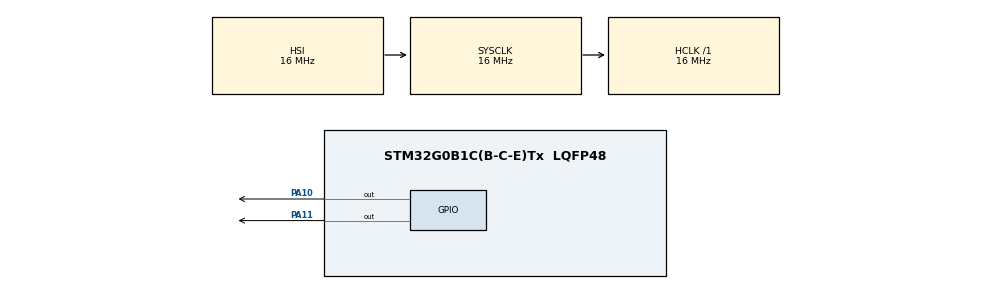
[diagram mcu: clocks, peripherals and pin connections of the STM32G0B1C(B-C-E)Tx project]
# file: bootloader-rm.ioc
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Mcu.Family=STM32G0
Mcu.Name=STM32G0B1C(B-C-E)Tx
Mcu.Package=LQFP48
PA10.Signal=GPIO_Output
PA11\ [PA9].Signal=GPIO_Output
PA2.Signal=USART2_TX
PA3.Signal=USART2_RX
ProjectManager.HeapSize=0x200
ProjectManager.StackSize=0x400
ProjectManager.TargetToolchain=STM32CubeIDE
RCC.AHBFreq_Value=16000000
RCC.CortexFreq_Value=16000000
RCC.EXTERNAL_CLOCK_VALUE=48000
RCC.HCLKFreq_Value=16000000
RCC.HSE_VALUE=8000000
RCC.HSI48_VALUE=48000000
RCC.HSI_VALUE=16000000
RCC.LSE_VALUE=32768
RCC.SYSCLKFreq_VALUE=16000000
RCC.USBFreq_Value=48000000
RCC.VCOOutputFreq_Value=128000000
VP_SYS_VS_DBSignals.Mode=DisableDeadBatterySignals
board=custom

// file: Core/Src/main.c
/* USER CODE BEGIN Header */
/**
  ******************************************************************************
  * @file           : main.c
  * @brief          : Main program body
  ******************************************************************************
  * @attention
  *
  * Copyright (c) 2024 STMicroelectronics.
  * All rights reserved.
  *
  * This software is licensed under terms that can be found in the LICENSE file
  * in the root directory of this software component.
  * If no LICENSE file comes with this software, it is provided AS-IS.
  *
  ******************************************************************************
  */
/* USER CODE END Header */
#include "main.h"

/* USER CODE BEGIN Includes */
#include "bootloader.h"
/* USER CODE END Includes */

void SystemClock_Config(void);
static void MX_GPIO_Init(void);

int main(void)
{

  /* MCU Configuration--------------------------------------------------------*/

  /* Reset of all peripherals, Initializes the Flash interface and the Systick. */
  HAL_Init();

  /* Configure the system clock */
  SystemClock_Config();

  /* Initialize all configured peripherals */
  MX_GPIO_Init();
  /* USER CODE BEGIN 2 */

  // Make sure that the boot0 pin will work
  if ( (FLASH->OPTR & FLASH_OPTR_nBOOT_SEL) != 0 ){
	  int a = 5;
//	  while(HAL_FLASH_Unlock() != HAL_OK);
//	  while(HAL_FLASH_OB_Unlock() != HAL_OK);
//
//	  /* Enable legacy mode (BOOT0 bit defined by BOOT0 pin) */
//	  /* by clearing the nBOOT_SELection bit */
//	  FLASH->OPTR &= ~FLASH_OPTR_nBOOT_SEL;
//
//	  /* check if there is any flash operation */
//	  while( (FLASH->SR & FLASH_SR_BSY1) != 0 )
//	    ;
//
//	  /* start the option byte flash */
//	  FLASH->CR |= FLASH_CR_OPTSTRT;
//	  /* wait until flashing is done */
//	  while( (FLASH->SR & FLASH_SR_BSY1) != 0 )
//	    ;
//
//	  while(HAL_FLASH_OB_Lock() != HAL_OK);
//	  while(HAL_FLASH_Lock() != HAL_OK);
  }

  /* USER CODE END 2 */

  /* Infinite loop */
  while (1)
  {

    /* USER CODE BEGIN 3 */
	  bootloader_run();
  }
  /* USER CODE END 3 */
}

void SystemClock_Config(void)
{
  RCC_OscInitTypeDef RCC_OscInitStruct = {0};
  RCC_ClkInitTypeDef RCC_ClkInitStruct = {0};

  /** Configure the main internal regulator output voltage
  */
  HAL_PWREx_ControlVoltageScaling(PWR_REGULATOR_VOLTAGE_SCALE1);

  /** Initializes the RCC Oscillators according to the specified parameters
  * in the RCC_OscInitTypeDef structure.
  */
  RCC_OscInitStruct.OscillatorType = RCC_OSCILLATORTYPE_HSI;
  RCC_OscInitStruct.HSIState = RCC_HSI_ON;
  RCC_OscInitStruct.HSIDiv = RCC_HSI_DIV1;
  RCC_OscInitStruct.HSICalibrationValue = RCC_HSICALIBRATION_DEFAULT;
  RCC_OscInitStruct.PLL.PLLState = RCC_PLL_NONE;
  if (HAL_RCC_OscConfig(&RCC_OscInitStruct) != HAL_OK)
  {
    Error_Handler();
  }

  /** Initializes the CPU, AHB and APB buses clocks
  */
  RCC_ClkInitStruct.ClockType = RCC_CLOCKTYPE_HCLK|RCC_CLOCKTYPE_SYSCLK
                              |RCC_CLOCKTYPE_PCLK1;
  RCC_ClkInitStruct.SYSCLKSource = RCC_SYSCLKSOURCE_HSI;
  RCC_ClkInitStruct.AHBCLKDivider = RCC_SYSCLK_DIV1;
  RCC_ClkInitStruct.APB1CLKDivider = RCC_HCLK_DIV1;

  if (HAL_RCC_ClockConfig(&RCC_ClkInitStruct, FLASH_LATENCY_0) != HAL_OK)
  {
    Error_Handler();
  }
}

static void MX_GPIO_Init(void)
{
  GPIO_InitTypeDef GPIO_InitStruct = {0};

  /* GPIO Ports Clock Enable */
  __HAL_RCC_GPIOA_CLK_ENABLE();

  /*Configure GPIO pin Output Level */
  HAL_GPIO_WritePin(GPIOA, GPIO_PIN_10|GPIO_PIN_11, GPIO_PIN_RESET);

  /*Configure GPIO pins : PA2 PA3 */
  GPIO_InitStruct.Pin = GPIO_PIN_2|GPIO_PIN_3;
  GPIO_InitStruct.Mode = GPIO_MODE_AF_PP;
  GPIO_InitStruct.Pull = GPIO_NOPULL;
  GPIO_InitStruct.Speed = GPIO_SPEED_FREQ_LOW;
  GPIO_InitStruct.Alternate = GPIO_AF1_USART2;
  HAL_GPIO_Init(GPIOA, &GPIO_InitStruct);

  /*Configure GPIO pins : PA10 PA11 */
  GPIO_InitStruct.Pin = GPIO_PIN_10|GPIO_PIN_11;
  GPIO_InitStruct.Mode = GPIO_MODE_OUTPUT_PP;
  GPIO_InitStruct.Pull = GPIO_NOPULL;
  GPIO_InitStruct.Speed = GPIO_SPEED_FREQ_LOW;
  HAL_GPIO_Init(GPIOA, &GPIO_InitStruct);

}

void Error_Handler(void)
{
  __disable_irq();
  while (1)
  {
  }
}
